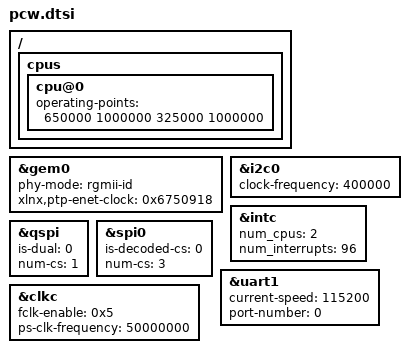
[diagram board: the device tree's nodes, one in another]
/*
 * CAUTION: This file is automatically generated by Xilinx.
 * Version: HSI 2016.2
 * Today is: Wed Aug  3 09:36:23 2016
*/


/ {
	cpus {
		cpu@0 {
			operating-points = <650000 1000000 325000 1000000>;
		};
	};
};
&gem0 {
	phy-mode = "rgmii-id";
	status = "okay";
	xlnx,ptp-enet-clock = <0x6750918>;
};
&i2c0 {
	clock-frequency = <400000>;
	status = "okay";
};
&intc {
	num_cpus = <2>;
	num_interrupts = <96>;
};
&qspi {
	is-dual = <0>;
	num-cs = <1>;
	status = "okay";
};
&spi0 {
	is-decoded-cs = <0>;
	num-cs = <3>;
	status = "okay";
};
&uart1 {
	current-speed = <115200>;
	device_type = "serial";
	port-number = <0>;
	status = "okay";
};
&clkc {
	fclk-enable = <0x5>;
	ps-clk-frequency = <50000000>;
};
